# icc_reva_me13 register map
Registers are read-only, no defined reset value unless marked. A register's access mark holds for its fields unless they carry their own. Offsets are from the block's base; lines under a group give offsets from that group; [hi:lo] are bit positions; {n}, {i} and the like mark numbered series; 'fields as' and 'values as' point back to an identical list; <NAME> marks a mode.

## Memory map
0x4002A000 ICC0 size 0x1000 — Instruction Cache Controller Registers

## ICC0 — Instruction Cache Controller Registers
Base 0x4002A000
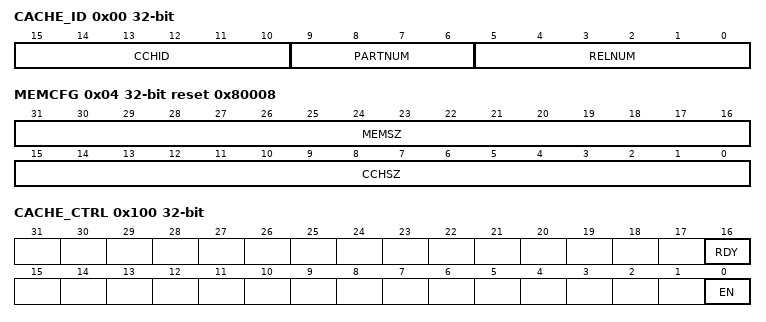
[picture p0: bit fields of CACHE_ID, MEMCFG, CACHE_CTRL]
0x00 CACHE_ID
  [15:10] CCHID — Cache ID. This field reflects the value of the C_ID_CACHEID configuration parameter.
  [9:6] PARTNUM — Part Number. This field reflects the value of C_ID_PART_NUMBER configuration parameter.
  [5:0] RELNUM — Release Number. Identifies the RTL release version.
0x04 MEMCFG reset 0x80008 — Memory Configuration Register.
  [31:16] MEMSZ — Main Memory Size. Indicates the total size, in units of 128 Kbytes, of code memory accessible to the cache controller.
  [15:0] CCHSZ — Cache Size. Indicates total size in Kbytes of cache.
0x100 CACHE_CTRL access not given — Cache Control and Status Register.
  [16] RDY ro — Cache Ready flag. Cleared by hardware when at any time the cache as a whole is invalidated (including a system reset). When this bit is 0, the cache is effectively in bypass mode (instruction fetches will come from main memory or from the line fill buffer). Set by hardware when the invalidate operation is complete and the cache is ready.
    0=invalid (Not Ready.); 1=ready
  [0] EN — Cache Enable. Controls whether the cache is bypassed or is in use. Changing the state of this bit will cause the instruction cache to be flushed and its contents invalidated.
    0=dis (Cache Bypassed. Instruction data is stored in the line fill buffer but is not written to main cache memory array.); 1=en (Cache Enabled.)
0x700 INVALIDATE rw — Invalidate All Registers.
  [31:0] INVALID — Invalidate.
